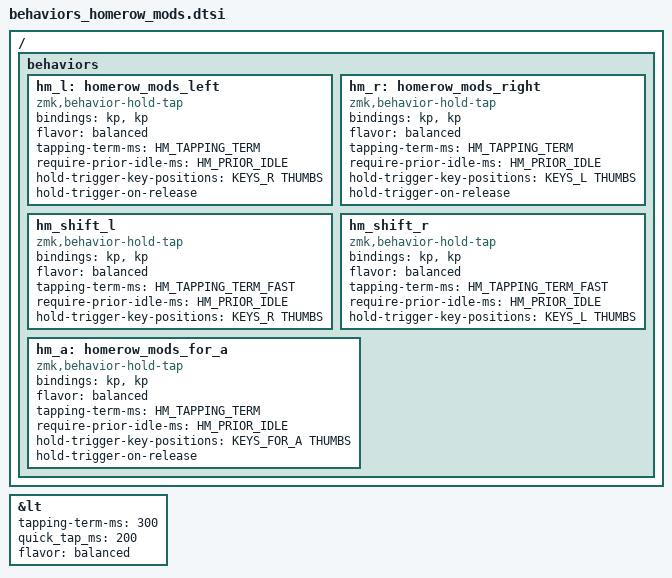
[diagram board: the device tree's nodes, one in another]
&lt {
    tapping-term-ms = <300>;
    quick_tap_ms = <200>;
    flavor = "balanced";
};
// #include "../../zmk-nodefree-config/keypos_def/keypos_36keys.h"

#define KEYS_L LT0 LT1 LT2 LT3 LT4 LM0 LM1 LM2 LM3 LM4 LB0 LB1 LB2 LB3 LB4
#define KEYS_R RT0 RT1 RT2 RT3 RT4 RM0 RM1 RM2 RM3 RM4 RB0 RB1 RB2 RB3 RB4
#define THUMBS LH2 LH1 LH0 RH0 RH1 RH2

// I keep getting false positives on 'al' (esp install), so make a set just
// for the a mod
#define KEYS_FOR_A RT0 RT1 RT2 RT3 RT4 RM0 RM1 RM2 RM3 RM4 RB0 RB1 RB2 RB3 RB4

#define HM_TAPPING_TERM 300
#define HM_TAPPING_TERM_FAST 200
#define HM_PRIOR_IDLE 175


// pulling this in direct from urob, seems like a nicer way to define these
// behaviours

// #define MAKE_HRM(NAME, HOLD, TAP, TRIGGER_POS) \
//     ZMK_BEHAVIOR(NAME, hold_tap, \
//         flavor = "balanced"; \
//         tapping-term-ms = <250>; \
//         require-prior-idle-ms = <require-prior-idle-ms>; \
//         require-prior-idle-ms = <150>; \
//         bindings = <HOLD>, <TAP>; \
//         hold-trigger-key-positions = <TRIGGER_POS>; \
//         hold-trigger-on-release; \
//     )
/ {

    behaviors {

        // Positional Homerow mods
        // Homerow mods that prevent accidental activations when rolling keys,
        // such as when typing `st` or `ne` on colemak-dh layouts or `as` on
        // qwerty.
        //
        // Works by only allowing a mod to activate within tapping-term if
        // it's on the opposite side of the keyboard or on the same side thumb
        // keys.

        // Further optimization using urob's timerless homerow mods method:
        // https://github.com/urob/zmk-config#timeless-homerow-mods
        hm_l: homerow_mods_left {
            compatible = "zmk,behavior-hold-tap";
            #binding-cells = <2>;
            bindings = <&kp>,  <&kp>;
            flavor = "balanced";
            tapping-term-ms = <HM_TAPPING_TERM>;
            require-prior-idle-ms = <HM_PRIOR_IDLE>; 
            hold-trigger-key-positions = <KEYS_R THUMBS>;
            hold-trigger-on-release;             // requires PR #1423
        };

        hm_r: homerow_mods_right {
            compatible = "zmk,behavior-hold-tap";
            #binding-cells = <2>;
            bindings = <&kp>, <&kp>;
            flavor = "balanced";
            tapping-term-ms = <HM_TAPPING_TERM>;
            require-prior-idle-ms = <HM_PRIOR_IDLE>;
            hold-trigger-key-positions = <KEYS_L THUMBS>;
            hold-trigger-on-release;             // requires PR #1423
        };

        // Positional Homerow mods for shift
        // Use faster tapping term and disable some features that may
        // cause false negatives.
        hm_shift_l: hm_shift_l {
            compatible = "zmk,behavior-hold-tap";
            #binding-cells = <2>;
            bindings = <&kp>, <&kp>;
            flavor = "balanced";
            tapping-term-ms = <HM_TAPPING_TERM_FAST>;
            require-prior-idle-ms = <HM_PRIOR_IDLE>;
            hold-trigger-key-positions = <KEYS_R THUMBS>;
            // hold-trigger-on-release;             // requires PR #1423
        };

        hm_shift_r: hm_shift_r {
            compatible = "zmk,behavior-hold-tap";
            #binding-cells = <2>;
            bindings = <&kp>, <&kp>;
            flavor = "balanced";
            tapping-term-ms = <HM_TAPPING_TERM_FAST>;
            require-prior-idle-ms = <HM_PRIOR_IDLE>;
            hold-trigger-key-positions = <KEYS_L THUMBS>;
            // hold-trigger-on-release;             // requires PR #1423
        };

        hm_a: homerow_mods_for_a {
            compatible = "zmk,behavior-hold-tap";
            #binding-cells = <2>;
            bindings = <&kp>,  <&kp>;
            flavor = "balanced";
            tapping-term-ms = <HM_TAPPING_TERM>;
            require-prior-idle-ms = <HM_PRIOR_IDLE>;
            hold-trigger-key-positions = <KEYS_FOR_A THUMBS>;
            hold-trigger-on-release;             // requires PR #1423
        };
    };
};
